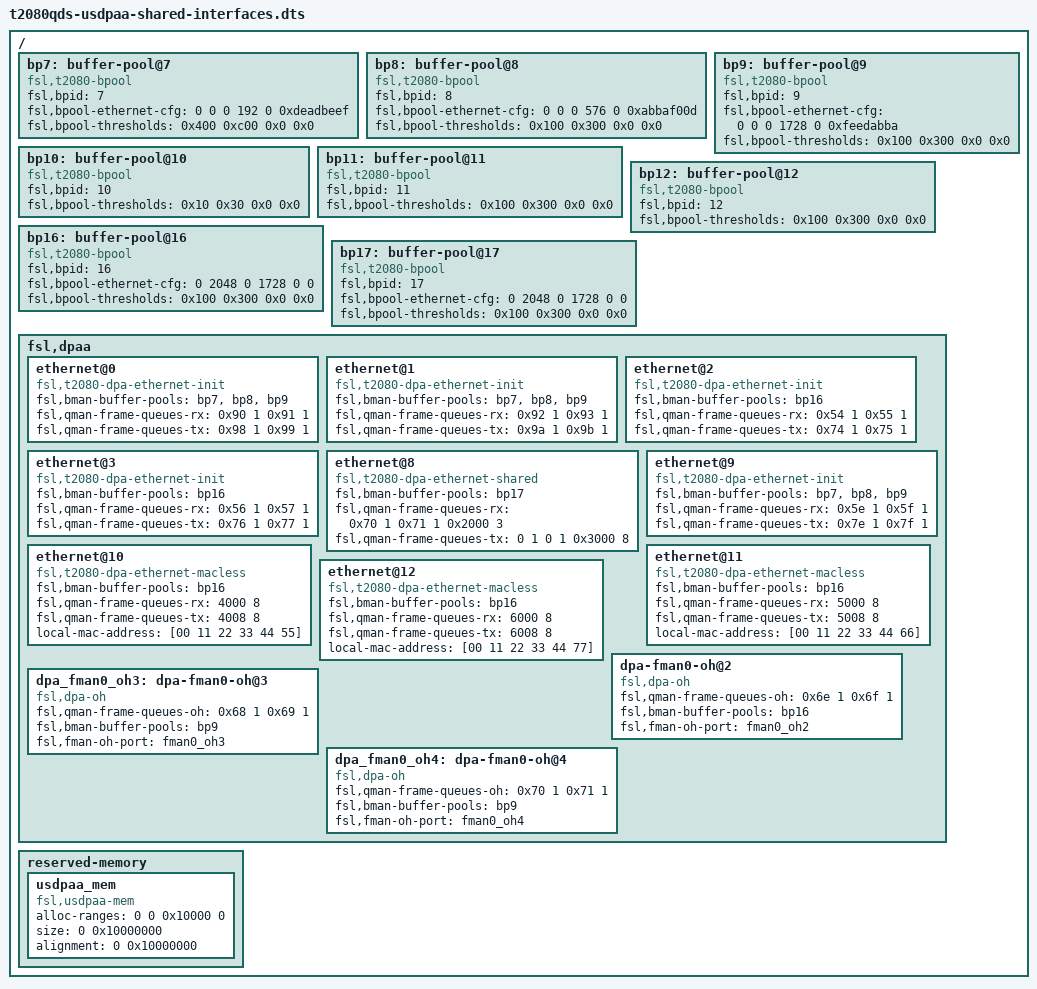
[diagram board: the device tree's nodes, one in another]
/*
 * T2080QDS USDPAA Device Tree Source
 *
 * Copyright 2014 Freescale Semiconductor Inc.
 *
 * Redistribution and use in source and binary forms, with or without
 * modification, are permitted provided that the following conditions are met:
 *     * Redistributions of source code must retain the above copyright
 *       notice, this list of conditions and the following disclaimer.
 *     * Redistributions in binary form must reproduce the above copyright
 *       notice, this list of conditions and the following disclaimer in the
 *       documentation and/or other materials provided with the distribution.
 *     * Neither the name of Freescale Semiconductor nor the
 *       names of its contributors may be used to endorse or promote products
 *       derived from this software without specific prior written permission.
 *
 *
 * ALTERNATIVELY, this software may be distributed under the terms of the
 * GNU General Public License ("GPL") as published by the Free Software
 * Foundation, either version 2 of that License or (at your option) any
 * later version.
 *
 * THIS SOFTWARE IS PROVIDED BY Freescale Semiconductor ``AS IS'' AND ANY
 * EXPRESS OR IMPLIED WARRANTIES, INCLUDING, BUT NOT LIMITED TO, THE IMPLIED
 * WARRANTIES OF MERCHANTABILITY AND FITNESS FOR A PARTICULAR PURPOSE ARE
 * DISCLAIMED. IN NO EVENT SHALL Freescale Semiconductor BE LIABLE FOR ANY
 * DIRECT, INDIRECT, INCIDENTAL, SPECIAL, EXEMPLARY, OR CONSEQUENTIAL DAMAGES
 * (INCLUDING, BUT NOT LIMITED TO, PROCUREMENT OF SUBSTITUTE GOODS OR SERVICES;
 * LOSS OF USE, DATA, OR PROFITS; OR BUSINESS INTERRUPTION) HOWEVER CAUSED AND
 * ON ANY THEORY OF LIABILITY, WHETHER IN CONTRACT, STRICT LIABILITY, OR TORT
 * (INCLUDING NEGLIGENCE OR OTHERWISE) ARISING IN ANY WAY OUT OF THE USE OF THIS
 * SOFTWARE, EVEN IF ADVISED OF THE POSSIBILITY OF SUCH DAMAGE.
 */

/include/ "t2080qds.dts"

/ {
	/* NB: "bpool-ethernet-seeds" is not set to avoid buffer seeding,
	 * because apps seed these pools with buffers allocated at
	 * run-time.
	 * HOWEVER, the kernel driver requires the buffer-size so
	 * "fsl,bpool-ethernet-cfg" is set. It also mis-interprets
	 * things if the base-address is zero (hence the 0xdeadbeef
	 * values).
	 */
	bp7: buffer-pool@7 {
		compatible = "fsl,t2080-bpool", "fsl,bpool";
		fsl,bpid = <7>;
		fsl,bpool-ethernet-cfg = <0 0 0 192 0 0xdeadbeef>;
		fsl,bpool-thresholds = <0x400 0xc00 0x0 0x0>;
	};
	bp8: buffer-pool@8 {
		compatible = "fsl,t2080-bpool", "fsl,bpool";
		fsl,bpid = <8>;
		fsl,bpool-ethernet-cfg = <0 0 0 576 0 0xabbaf00d>;
		fsl,bpool-thresholds = <0x100 0x300 0x0 0x0>;
	};
	bp9: buffer-pool@9 {
		compatible = "fsl,t2080-bpool", "fsl,bpool";
		fsl,bpid = <9>;
		fsl,bpool-ethernet-cfg = <0 0 0 1728 0 0xfeedabba>;
		fsl,bpool-thresholds = <0x100 0x300 0x0 0x0>;
	};

	bp10: buffer-pool@10 {
		compatible = "fsl,t2080-bpool", "fsl,bpool";
		fsl,bpid = <10>;
		fsl,bpool-thresholds = <0x10 0x30 0x0 0x0>;
	};
	bp11: buffer-pool@11 {
		compatible = "fsl,t2080-bpool", "fsl,bpool";
		fsl,bpid = <11>;
		fsl,bpool-thresholds = <0x100 0x300 0x0 0x0>;
	};
	bp12: buffer-pool@12 {
		compatible = "fsl,t2080-bpool", "fsl,bpool";
		fsl,bpid = <12>;
		fsl,bpool-thresholds = <0x100 0x300 0x0 0x0>;
	};
	bp16: buffer-pool@16 {
                        compatible = "fsl,t2080-bpool", "fsl,bpool";
                        fsl,bpid = <16>;
                        fsl,bpool-ethernet-cfg = <0 2048 0 1728 0 0>;
                        fsl,bpool-thresholds = <0x100 0x300 0x0 0x0>;
       };
	bp17: buffer-pool@17 {
                        compatible = "fsl,t2080-bpool", "fsl,bpool";
                        fsl,bpid = <17>;
                        fsl,bpool-ethernet-cfg = <0 2048 0 1728 0 0>;
                        fsl,bpool-thresholds = <0x100 0x300 0x0 0x0>;
       };

	fsl,dpaa {
		ethernet@0 {/* 10G */
			compatible = "fsl,t2080-dpa-ethernet-init", "fsl,dpa-ethernet-init";
			fsl,bman-buffer-pools = <&bp7 &bp8 &bp9>;
			fsl,qman-frame-queues-rx = <0x90 1 0x91 1>;
			fsl,qman-frame-queues-tx = <0x98 1 0x99 1>;
		};
		ethernet@1 {/* 10G */
			compatible = "fsl,t2080-dpa-ethernet-init", "fsl,dpa-ethernet-init";
			fsl,bman-buffer-pools = <&bp7 &bp8 &bp9>;
			fsl,qman-frame-queues-rx = <0x92 1 0x93 1>;
			fsl,qman-frame-queues-tx = <0x9a 1 0x9b 1>;
		};
		ethernet@2 {/* 1G */
			compatible = "fsl,t2080-dpa-ethernet-init", "fsl,dpa-ethernet-init";
			fsl,bman-buffer-pools = <&bp16>;
			fsl,qman-frame-queues-rx = <0x54 1 0x55 1>;
			fsl,qman-frame-queues-tx = <0x74 1 0x75 1>;
		};
		ethernet@3 {/* 1G */
			compatible = "fsl,t2080-dpa-ethernet-init", "fsl,dpa-ethernet-init";
			fsl,bman-buffer-pools = <&bp16>;
			fsl,qman-frame-queues-rx = <0x56 1 0x57 1>;
			fsl,qman-frame-queues-tx = <0x76 1 0x77 1>;
		};
		/* ethernet@8 declared as shared MAC. USDPAA will seed buffers to
		 * this buffer pool. The ethernet driver will initialize the RX default,
		 * RX error, TX error, TX confirm and 8 TX Frame queues. On receiving frame
		 * at this interface, the ethernet driver will do kmap_atomic/kunmap_atomic
		 * for that frame. */
		ethernet@8 {/* 10G */
			compatible = "fsl,t2080-dpa-ethernet-shared", "fsl,dpa-ethernet-shared";
			fsl,bman-buffer-pools = <&bp17>;
			fsl,qman-frame-queues-rx = <0x70 1 0x71 1 0x2000 3>;
                        fsl,qman-frame-queues-tx = <0 1 0 1 0x3000 8>;
		};
		ethernet@9 {/* 10G */
			compatible = "fsl,t2080-dpa-ethernet-init", "fsl,dpa-ethernet-init";
			fsl,bman-buffer-pools = <&bp7 &bp8 &bp9>;
			fsl,qman-frame-queues-rx = <0x5e 1 0x5f 1>;
			fsl,qman-frame-queues-tx = <0x7e 1 0x7f 1>;
		};
		/* ethernet@10 declared as MAC-less interface with no "fsl,fman-mac" property.
		 * USDPAA will seed buffers to this buffer pool and initialize 8 TX Frame
		 * queues. The ethernet driver will initialize 8 RX default Frame queues.
		 * On receiving frame at this interface, the ethernet driver will do
		 * kmap_atomic/kunmap_atomic for that frame. */
		ethernet@10 {
			compatible = "fsl,t2080-dpa-ethernet-macless", "fsl,dpa-ethernet-macless";
			fsl,bman-buffer-pools = <&bp16>;
			fsl,qman-frame-queues-rx = <4000 8>;
			fsl,qman-frame-queues-tx = <4008 8>;
			local-mac-address = [00 11 22 33 44 55];
		};
		ethernet@11 {
			compatible = "fsl,t2080-dpa-ethernet-macless", "fsl,dpa-ethernet-macless";
			fsl,bman-buffer-pools = <&bp16>;
			fsl,qman-frame-queues-rx = <5000 8>;
			fsl,qman-frame-queues-tx = <5008 8>;
			local-mac-address = [00 11 22 33 44 66];
		};
		ethernet@12 {
			compatible = "fsl,t2080-dpa-ethernet-macless", "fsl,dpa-ethernet-macless";
			fsl,bman-buffer-pools = <&bp16>;
			fsl,qman-frame-queues-rx = <6000 8>;
			fsl,qman-frame-queues-tx = <6008 8>;
			local-mac-address = [00 11 22 33 44 77];
		};
		dpa-fman0-oh@2 {
			compatible = "fsl,dpa-oh";
			/* Define frame queues for the OH port*/
			/* <OH Rx error, OH Rx default> */
			fsl,qman-frame-queues-oh = <0x6e 1 0x6f 1>;
			fsl,bman-buffer-pools = <&bp16>;
			fsl,fman-oh-port = <&fman0_oh2>;
		};
		dpa_fman0_oh3: dpa-fman0-oh@3 {
			compatible = "fsl,dpa-oh";
			fsl,qman-frame-queues-oh = <0x68 1 0x69 1>;
			fsl,bman-buffer-pools = <&bp9>;
			fsl,fman-oh-port = <&fman0_oh3>;
		};
		dpa_fman0_oh4: dpa-fman0-oh@4 {
			compatible = "fsl,dpa-oh";
			fsl,qman-frame-queues-oh = <0x70 1 0x71 1>;
			fsl,bman-buffer-pools = <&bp9>;
			fsl,fman-oh-port = <&fman0_oh4>;
		};
	};
	reserved-memory {
		#address-cells = <2>;
		#size-cells = <2>;
		ranges;

		usdpaa_mem: usdpaa_mem {
			compatible = "fsl,usdpaa-mem";
			alloc-ranges = <0 0 0x10000 0>;
			size = <0 0x10000000>;
			alignment = <0 0x10000000>;
		};
	};
};
